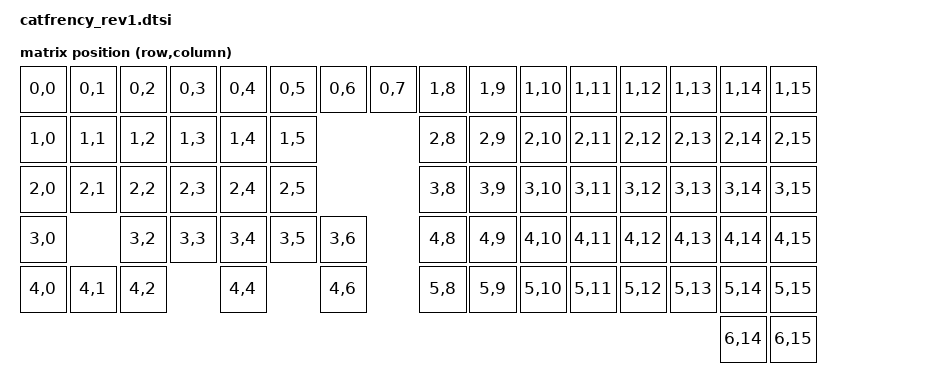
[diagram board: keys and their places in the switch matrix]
// This file was generated from a template. Edit it to match your keyboard.
// See https://zmk.dev/docs/development/hardware-integration/new-shield for more
// instructions.

#include <dt-bindings/zmk/matrix_transform.h>

#include "catfrency_rev1-layouts.dtsi"



/ {
    chosen {
        zmk,physical-layout = &default_layout;
        zmk,kscan = &kscan;
        zmk,matrix-transform = &default_transform;
    };


    default_layout: default_layout {
        compatible = "zmk,physical-layout";
        display-name = "asdfasdf Layout";
        transform = <&default_transform>;
        kscan = <&kscan>;
        // If you're not adding ZMK Studio support, you can stop here.
        // If you are, you also need a `keys = <...>` property describing
        // each key's physical position/size — see the physical layouts
        // guide.
    };

    kscan: kscan {
        compatible = "zmk,kscan-gpio-matrix";
        wakeup-source;
        diode-direction = "col2row"; // or "row2col" — match your PCB's diode wiring
    };

    default_transform: default_transform {
        // See https://zmk.dev/docs/development/hardware-integration/new-shield#matrix-transform
        // for how to configure this
        compatible = "zmk,matrix-transform";
        columns = <16>;
        rows = <7>;

        map = <
            RC(0, 0) RC(0, 1) RC(0, 2) RC(0, 3) RC(0, 4) RC(0, 5) RC(0, 6) RC(0, 7)     RC(1, 8) RC(1, 9) RC(1, 10) RC(1, 11) RC(1, 12) RC(1, 13) RC(1, 14) RC(1, 15)  
            RC(1, 0) RC(1, 1) RC(1, 2) RC(1, 3) RC(1, 4) RC(1, 5)                       RC(2, 8) RC(2, 9) RC(2, 10) RC(2, 11) RC(2, 12) RC(2, 13) RC(2, 14) RC(2, 15) 
            RC(2, 0) RC(2, 1) RC(2, 2) RC(2, 3) RC(2, 4) RC(2, 5)                       RC(3, 8) RC(3, 9) RC(3, 10) RC(3, 11) RC(3, 12) RC(3, 13) RC(3, 14) RC(3, 15)
            RC(3, 0)          RC(3, 2) RC(3, 3) RC(3, 4) RC(3, 5) RC(3, 6)              RC(4, 8) RC(4, 9) RC(4, 10) RC(4, 11) RC(4, 12) RC(4, 13) RC(4, 14) RC(4, 15) 
            RC(4, 0) RC(4, 1) RC(4, 2)          RC(4, 4)          RC(4, 6)              RC(5, 8) RC(5, 9) RC(5, 10) RC(5, 11) RC(5, 12) RC(5, 13) RC(5, 14) RC(5, 15) 
                                                                                                                                              RC(6, 14) RC(6, 15)
        >;
    };
};
